# MSP432P411V register map
Vendor: Texas Instruments; File version: 3.230
Registers are 32-bit, read-write, reset 0x0 unless marked. A register's access mark holds for its fields unless they carry their own. Offsets are from the block's base; [hi:lo] are bit positions; {n}, {i} and the like mark numbered series; 'fields as' and 'values as' point back to an identical list.

## CRC32
Base 0x40004000
0x00 CRC32DI 16-bit — Data Input for CRC32 Signature Computation
  [15:0] CRC32DI — Data input register
0x04 CRC32DIRB 16-bit — Data In Reverse for CRC32 Computation
  [15:0] CRC32DIRB — Data input register reversed
0x08 CRC32INIRES_LO 16-bit — CRC32 Initialization and Result, lower 16 bits
  [15:0] CRC32INIRES_LO — CRC32 initialization and result, lower 16 bits
0x0A CRC32INIRES_HI 16-bit — CRC32 Initialization and Result, upper 16 bits
  [15:0] CRC32INIRES_HI — CRC32 initialization and result, upper 16 bits
0x0C CRC32RESR_LO 16-bit reset 0xFFFF — CRC32 Result Reverse, lower 16 bits
  [15:0] CRC32RESR_LO — CRC32 reverse result, lower 16 bits
0x0E CRC32RESR_HI 16-bit reset 0xFFFF — CRC32 Result Reverse, Upper 16 bits
  [15:0] CRC32RESR_HI — CRC32 reverse result, upper 16 bits
0x10 CRC16DI 16-bit — Data Input for CRC16 computation
  [15:0] CRC16DI — CRC16 data in
0x14 CRC16DIRB 16-bit — CRC16 Data In Reverse
  [15:0] CRC16DIRB — CRC16 data in reverse byte
0x18 CRC16INIRES 16-bit reset 0xFFFF — CRC16 Initialization and Result register
  [15:0] CRC16INIRES — CRC16 initialization and result
0x1E CRC16RESR 16-bit reset 0xFFFF — CRC16 Result Reverse
  [15:0] CRC16RESR — CRC16 reverse result

## WDT_A
Base 0x40004800
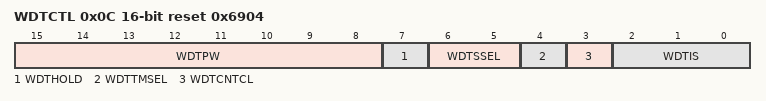
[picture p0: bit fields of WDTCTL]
0x0C WDTCTL 16-bit reset 0x6904 — Watchdog Timer Control Register
  [15:8] WDTPW — Watchdog timer password
  [7] WDTHOLD — Watchdog timer hold
    0=Watchdog timer is not stopped; 1=Watchdog timer is stopped
  [6:5] WDTSSEL — Watchdog timer clock source select
    0=SMCLK; 1=ACLK; 2=VLOCLK; 3=BCLK
  [4] WDTTMSEL — Watchdog timer mode select
    0=Watchdog mode; 1=Interval timer mode
  [3] WDTCNTCL wo — Watchdog timer counter clear
    on write: 0=No action; 1=WDTCNT = 0000h
  [2:0] WDTIS — Watchdog timer interval select
    0=Watchdog clock source / (2^(31)) (18:12:16 at 32.768 kHz); 1=Watchdog clock source /(2^(27)) (01:08:16 at 32.768 kHz); 2=Watchdog clock source /(2^(23)) (00:04:16 at 32.768 kHz); 3=Watchdog clock source /(2^(19)) (00:00:16 at 32.768 kHz); 4=Watchdog clock source /(2^(15)) (1 s at 32.768 kHz); 5=Watchdog clock source / (2^(13)) (250 ms at 32.768 kHz); 6=Watchdog clock source / (2^(9)) (15.625 ms at 32.768 kHz); 7=Watchdog clock source / (2^(6)) (1.95 ms at 32.768 kHz)

## CAPTIO0
Base 0x40005400
Same registers: CAPTIO1 0x40005800
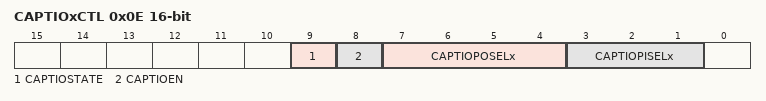
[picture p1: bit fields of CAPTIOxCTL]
0x0E CAPTIOxCTL 16-bit — Capacitive Touch IO x Control Register
  [9] CAPTIOSTATE ro — Capacitive Touch IO state
    on read: 0=Curent state 0 or Capacitive Touch IO is disabled; 1=Current state 1
  [8] CAPTIOEN — Capacitive Touch IO enable
    0=All Capacitive Touch IOs are disabled. Signal towards timers is 0.; 1=Selected Capacitive Touch IO is enabled
  [7:4] CAPTIOPOSELx — Capacitive Touch IO port select
    0=Px = PJ; {v}=Px = P{v} (v=1..15)
  [3:1] CAPTIOPISELx — Capacitive Touch IO pin select
    0=Px.0; 1=Px.1; 2=Px.2; 3=Px.3; 4=Px.4; 5=Px.5; 6=Px.6; 7=Px.7

## TIMER32
Base 0x4000C000
0x00 T32LOAD1 — Timer 1 Load Register
  [31:0] LOAD — The value from which the Timer 1 counter decrements
0x04 T32VALUE1 ro reset 0xFFFFFFFF — Timer 1 Current Value Register
  [31:0] VALUE — Current value
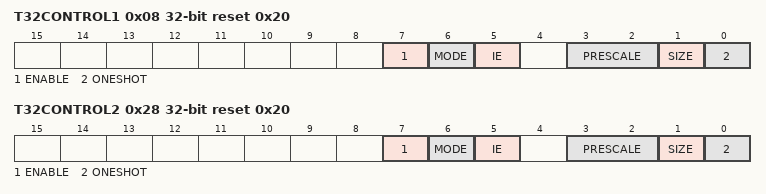
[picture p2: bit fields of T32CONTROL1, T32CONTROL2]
0x08 T32CONTROL1 reset 0x20 — Timer 1 Timer Control Register
  [7] ENABLE — Enable bit
    0=Timer disabled; 1=Timer enabled
  [6] MODE — Mode bit
    0=Timer is in free-running mode; 1=Timer is in periodic mode
  [5] IE — Interrupt enable bit
    0=Timer interrupt disabled; 1=Timer interrupt enabled
  [3:2] PRESCALE — Prescale bits
    0=0 stages of prescale, clock is divided by 1; 1=4 stages of prescale, clock is divided by 16; 2=8 stages of prescale, clock is divided by 256
  [1] SIZE — Selects 16 or 32 bit counter operation
    0=16-bit counter; 1=32-bit counter
  [0] ONESHOT — Selects one-shot or wrapping counter mode
    0=wrapping mode; 1=one-shot mode
0x0C T32INTCLR1 wo reset not defined — Timer 1 Interrupt Clear Register
  [31:0] INTCLR — Write clears interrupt output
0x10 T32RIS1 ro — Timer 1 Raw Interrupt Status Register
  [0] RAW_IFG — Raw interrupt status
0x14 T32MIS1 ro — Timer 1 Interrupt Status Register
  [0] IFG — Enabled interrupt status
0x18 T32BGLOAD1 — Timer 1 Background Load Register
  [31:0] BGLOAD — Value from which the counter decrements
0x20 T32LOAD2 — Timer 2 Load Register
  [31:0] LOAD — The value from which the Timer 2 counter decrements
0x24 T32VALUE2 ro reset 0xFFFFFFFF — Timer 2 Current Value Register
  [31:0] VALUE — Current value of the decrementing counter
0x28 T32CONTROL2 reset 0x20 — Timer 2 Timer Control Register
  fields as T32CONTROL1
0x2C T32INTCLR2 wo reset not defined — Timer 2 Interrupt Clear Register
  [31:0] INTCLR — Write clears the interrupt output
0x30 T32RIS2 ro — Timer 2 Raw Interrupt Status Register
  [0] RAW_IFG — Raw interrupt status
0x34 T32MIS2 ro — Timer 2 Interrupt Status Register
  [0] IFG — Enabled interrupt status
0x38 T32BGLOAD2 — Timer 2 Background Load Register
  [31:0] BGLOAD — Value from which the counter decrements

## Notices in the file
Copyright (C) 2012-2018 Texas Instruments Incorporated - http://www.ti.com
Redistribution and use in source and binary forms, with or without
modification, are permitted provided that the following conditions
are met:
Redistributions of source code must retain the above copyright
notice, this list of conditions and the following disclaimer.
Redistributions in binary form must reproduce the above copyright
notice, this list of conditions and the following disclaimer in the
documentation and/or other materials provided with the
distribution.
Neither the name of Texas Instruments Incorporated nor the names of
its contributors may be used to endorse or promote products derived
from this software without specific prior written permission.
THIS SOFTWARE IS PROVIDED BY THE COPYRIGHT HOLDERS AND CONTRIBUTORS
"AS IS" AND ANY EXPRESS OR IMPLIED WARRANTIES, INCLUDING, BUT NOT
LIMITED TO, THE IMPLIED WARRANTIES OF MERCHANTABILITY AND FITNESS FOR
A PARTICULAR PURPOSE ARE DISCLAIMED. IN NO EVENT SHALL THE COPYRIGHT
OWNER OR CONTRIBUTORS BE LIABLE FOR ANY DIRECT, INDIRECT, INCIDENTAL,
SPECIAL, EXEMPLARY, OR CONSEQUENTIAL DAMAGES (INCLUDING, BUT NOT
LIMITED TO, PROCUREMENT OF SUBSTITUTE GOODS OR SERVICES; LOSS OF USE,
DATA, OR PROFITS; OR BUSINESS INTERRUPTION) HOWEVER CAUSED AND ON ANY
THEORY OF LIABILITY, WHETHER IN CONTRACT, STRICT LIABILITY, OR TORT
(INCLUDING NEGLIGENCE OR OTHERWISE) ARISING IN ANY WAY OUT OF THE USE
OF THIS SOFTWARE, EVEN IF ADVISED OF THE POSSIBILITY OF SUCH DAMAGE.
